# A31T21x register map
Vendor: ABOV Semiconductor Co., Ltd.; Series: A31T21x; File version: 1.0
CPU: CM0PLUS r0p1, little endian, no MPU, no FPU, VTOR, 2 interrupt priority bits
Registers are 32-bit, read-write, reset 0x0 unless marked. A register's access mark holds for its fields unless they carry their own. Offsets are from the block's base; [hi:lo] are bit positions.

## WT — WATCH TIMER
Base 0x40002000
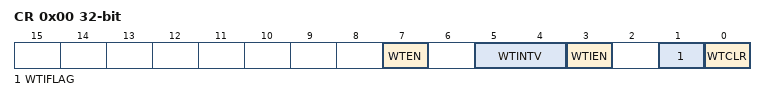
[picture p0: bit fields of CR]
0x00 CR — Watch Timer Control Register
  [7] WTEN — Watch Timer Operation Enable bit
    0=DISABLE_WT (Disable watch timer operation); 1=ENABLE_WT (Enable watch timer operation)
  [5:4] WTINTV — Watch Timer Interval Selection bits.
    0=WT_IF_INTERVAL_7 (fWT/2^7); 1=WT_IF_INTERVAL_13 (fWT/2^13); 2=WT_IF_INTERVAL_14 (fWT/2^14); 3=WT_IF_INTERVAL_14_ (fWT/(2^14x(WTDR value + 1)))
  [3] WTIEN — Watch Timer Interrupt Enable bit
    0=DISABLE_WT_INT (Disable watch timer interrupt); 1=ENABLE_WT_INT (Enable watch timer interrupt)
  [1] WTIFLAG — Watch Timer Interrupt Flag bit
    0=WT_IF_CLR (No request occurred); 1=WT_IF_SET (Request occurred, This bit is cleared to '0' when write '1'.)
  [0] WTCLR — Watch Timer Counter and Divider Clear bit
    0=LET_WT_CNT_BE (No effect); 1=CLEAR_WT_CNT (Clear the counter and divider (Automatically cleared to "0b" after operation))
0x04 DR reset 0xFFF — Watch Timer Data Register
  [11:0] WTDATA — Watch Timer Data bits. The range is 0x001 to 0xFFF.
0x08 CNT ro — Watch Timer Counter Register
  [11:0] CNT — Watch Timer Counter bits.

## TIMER10 — TIMER COUNTER 10/11/12
Base 0x40002100
Same registers: TIMER11 0x40002200, TIMER12 0x40002300, TIMER13 0x40002700
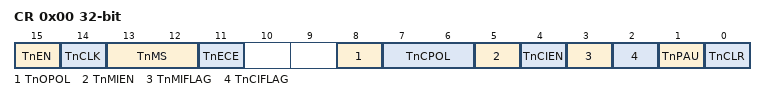
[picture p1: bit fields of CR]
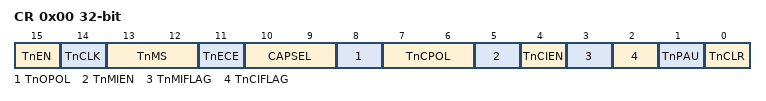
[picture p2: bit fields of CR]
0x00 CR — Timer/Counter n Control Register
  [15] TnEN — Timer n Operation Enable bit
  [14] TnCLK — Timer n Clock Selection bit (Note: This bit should be changed during TnEN bit is "0b".)
  [13:12] TnMS — Timer n Operation Mode Selection bits (Note: These bits should be changed during TnEN bit is "0b".)
  [11] TnECE — Timer n External Clock Edge Selection bit
  [8] TnOPOL — TnOUT Polarity Selection bit
  [7:6] TnCPOL — Timer n Capture Polarity Selection bits
  [5] TnMIEN — Timer n Match Interrupt Enable bit
  [4] TnCIEN — Timer n Capture Interrupt Enable bit
  [3] TnMIFLAG — Timer n Match Interrupt Flag bit
  [2] TnCIFLAG — Timer n Capture Interrupt Flag bit
  [1] TnPAU — Timer n Counter Temporary Pause Control bit
  [0] TnCLR — Timer n Counter and Prescaler Clear bit
0x04 ADR reset 0xFFFF — Timer/Counter n A Data Register
  [15:0] ADATA — Timer/Counter n A Data bits. The range is 0x0000 to 0xFFFF. Note: Do not write "0000H" in the TnADR register when PPG mode.
0x08 BDR reset 0xFFFF — Timer/Counter n B Data Register
  [15:0] BDATA — Timer/Counter n B Data bits. The range is 0x0000 to 0xFFFF.
0x0C CAPDR ro — Timer/Counter n Capture Data Register
  [15:0] CAPD — Timer/Counter n Capture Data bits.
0x10 PREDR reset 0xFFF — Timer/Counter n Prescaler Data Register
  [11:0] PRED — Timer/Counter n Prescaler Data bits.
0x14 CNT ro — Timer/Counter n Counter Register
  [15:0] CNT — Timer/Counter n Counter bits.

## TIMER20 — TIMER COUNTER 20/21
Base 0x40002500
Same registers: TIMER21 0x40002600
0x00 CR — Timer/Counter n Control Register
  [15] TnEN — Timer n Operation Enable bit
  [14] TnCLK — Timer n Clock Selection bit (Note: This bit should be changed during TnEN bit is "0b".)
  [13:12] TnMS — Timer n Operation Mode Selection bits (Note: These bits should be changed during TnEN bit is "0b".)
  [11] TnECE — Timer n External Clock Edge Selection bit
  [10:9] CAPSEL — Timer n Capture Signal Selection bits
  [8] TnOPOL — TnOUT Polarity Selection bit
  [7:6] TnCPOL — Timer n Capture Polarity Selection bits
  [5] TnMIEN — Timer n Match Interrupt Enable bit
  [4] TnCIEN — Timer n Capture Interrupt Enable bit
  [3] TnMIFLAG — Timer n Match Interrupt Flag bit
  [2] TnCIFLAG — Timer n Capture Interrupt Flag bit
  [1] TnPAU — Timer n Counter Temporary Pause Control bit
  [0] TnCLR — Timer n Counter and Prescaler Clear bit
0x04 ADR reset 0xFFFFFFFF — Timer/Counter n A Data Register
  [31:0] ADATA — Timer/Counter n A Data bits. The range is 0x00000000 to 0xFFFFFFFF. Note: Do not write "00000000H" in the TnADR register when PPG mode.
0x08 BDR reset 0xFFFFFFFF — Timer/Counter n B Data Register
  [31:0] BDATA — Timer/Counter n B Data bits. The range is 0x00000000 to 0xFFFFFFFF.
0x0C CAPDR ro — Timer/Counter n Capture Data Register
  [31:0] CAPD — Timer/Counter n Capture Data bits.
0x10 PREDR reset 0xFFF — Timer/Counter n Prescaler Data Register
  [11:0] PRED — Timer/Counter n Prescaler Data bits.P
0x14 CNT ro — Timer/Counter n Counter Register
  [31:0] CNT — Timer/Counter n Counter bits.
